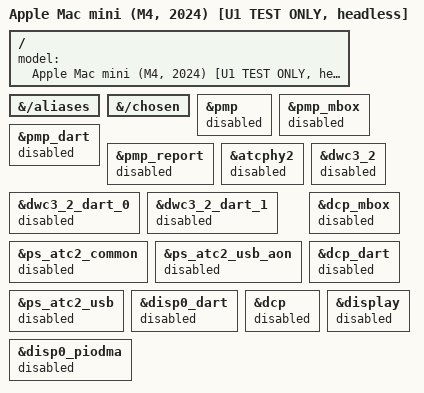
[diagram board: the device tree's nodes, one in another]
// SPDX-License-Identifier: GPL-2.0+ OR MIT
/*
 * TEST ONLY - not for upstream.
 *
 * The U1 tree with the PMP, G16 GPU, display engines and every USB controller
 * disabled.  The HDMI output stays on the boot loader's framebuffer only.
 * U1's hard-coded display carveouts are dropped, so this tree reserves
 * nothing the loader does not.  Loader aliases for those disabled devices are
 * removed too: aura must not turn an R1 device back on while preparing Linux.
 */

#include "t8132-j773g-u1-nogpu.dts"

/ {
	model = "Apple Mac mini (M4, 2024) [U1 TEST ONLY, headless]";
};

&{/aliases} {
	/delete-property/ atcphy0;
	/delete-property/ atcphy1;
	/delete-property/ atcphy2;
	/delete-property/ atcphy3;
	/delete-property/ dcp;
	/delete-property/ dcpext0;
	/delete-property/ dcpext1;
	/delete-property/ disp0;
	/delete-property/ gpu;
	/delete-property/ pmp;
};

&{/chosen} {
	/delete-property/ linux-enablement-mac,dapf-handoff;
	/delete-property/ linux-enablement-mac,dapf-power-on-handoff;
};

/delete-node/ &u1_asc_fw;
/delete-node/ &u1_dcp_data;
/delete-node/ &u1_framebuffer;
/delete-node/ &u1_region95;
/delete-node/ &u1_region94;
/delete-node/ &u1_region57;
/delete-node/ &dptx_phy_u1;

&pmp {
	status = "disabled";
};

&pmp_mbox {
	status = "disabled";
};

&pmp_dart {
	status = "disabled";
};

&pmp_report {
	status = "disabled";
};

&atcphy2 {
	status = "disabled";
};

&dwc3_2_dart_0 {
	status = "disabled";
};

&dwc3_2_dart_1 {
	status = "disabled";
};

&dwc3_2 {
	status = "disabled";
};

&ps_atc2_common {
	status = "disabled";
};

&ps_atc2_usb_aon {
	status = "disabled";
};

&ps_atc2_usb {
	status = "disabled";
};

&dcp_mbox {
	status = "disabled";
};

&dcp_dart {
	status = "disabled";
};

&disp0_dart {
	status = "disabled";
};

&dcp {
	/delete-property/ aurora,j773g-hdmi-test;
	/delete-property/ memory-region;
	/delete-property/ memory-region-names;
	/delete-property/ phys;
	/delete-property/ phy-names;
	/delete-property/ clocks;
	status = "disabled";
};

&disp0_piodma {
	/delete-property/ memory-region;
	/delete-property/ memory-region-names;
	status = "disabled";
};

&display {
	/delete-property/ memory-region;
	/delete-property/ memory-region-names;
	status = "disabled";
};
